# COMPUTE_CLUSTER_J7AHP0_C71SS0_0_AW4_MSMC1_CFGS0 register map
Vendor: Texas Instruments
Peripheral module from a debugger description file (folder J7_AHP).
Registers are 64-bit, read-write, reset values left out (the file's numbers can be read two ways) unless marked. A register's access mark holds for its fields unless they carry their own. Offsets are as the file gives them; lines under a group give offsets from that group; [hi:lo] are bit positions; {n}, {i} and the like mark numbered series; 'fields as' and 'values as' point back to an identical list; <NAME> marks a mode.

## COMPUTE_CLUSTER_J7AHP0_C71SS0_0_AW4_MSMC1_CFGS0
0x00 AW4_MSMC1_CFGS0_pid ro
  [31:0] REVISION — PID Revision
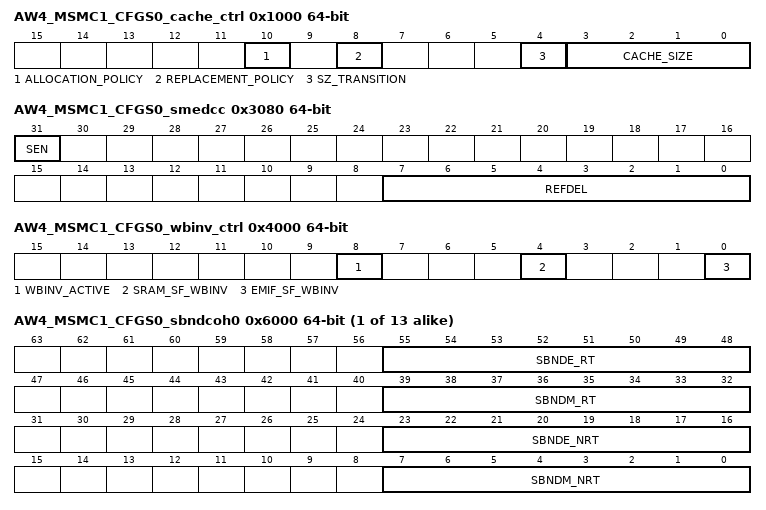
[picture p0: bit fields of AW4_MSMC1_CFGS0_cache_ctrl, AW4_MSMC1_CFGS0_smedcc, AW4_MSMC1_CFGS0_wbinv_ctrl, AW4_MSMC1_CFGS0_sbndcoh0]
0x1000 AW4_MSMC1_CFGS0_cache_ctrl access per field
  [10] ALLOCATION_POLICY rw
  [8] REPLACEMENT_POLICY rw
  [4] SZ_TRANSITION ro — Cache Size Change in Progress
  [3:0] CACHE_SIZE rw — Cache Size Control
0x1008 AW4_MSMC1_CFGS0_cache_stat access not given
0x2048 AW4_MSMC1_CFGS0_cohctrl
  [0] BCM — Broadcast Mode
0x3080 AW4_MSMC1_CFGS0_smedcc
  [31] SEN — Scrub Engine Enable
  [7:0] REFDEL — Number of Clock Cycles Between Scrubs
0x4000 AW4_MSMC1_CFGS0_wbinv_ctrl access per field
  [8] WBINV_ACTIVE ro — Writeback Invalidate in Progress
  [4] SRAM_SF_WBINV wo — SRAM Snoop Filter Writeback Invalidation Trigger
  [0] EMIF_SF_WBINV wo — EMIF Snoop Filter Writeback Invalidation Trigger
0x5000 AW4_MSMC1_CFGS0_smestat ro
  [0] NULL_SLV — Null slave error is enabled and pending
0x5008 AW4_MSMC1_CFGS0_smirstat ro
  [0] NULL_SLV — Null slave error flagged
0x5008 AW4_MSMC1_CFGS0_smirws wo
  [0] NULL_SLV — Set software null slave error
0x5010 AW4_MSMC1_CFGS0_smirc wo
  [0] NULL_SLV — Clear null slave error flag
0x5018 AW4_MSMC1_CFGS0_smiestat ro
  [0] NULL_SLV — Null slave error interrupt is enabled
0x5018 AW4_MSMC1_CFGS0_smiews wo
  [0] NULL_SLV — Enable null slave error
0x5020 AW4_MSMC1_CFGS0_smiec wo
  [0] NULL_SLV — clear null slave error interrupt enable
{0x6000+8i} AW4_MSMC1_CFGS0_sbndcoh{i} (i=0..12)
  [55:48] SBNDE_RT — Starvation Bound for Real-Time External Memory
  [39:32] SBNDM_RT — Starvation Bound for Real-Time On-Chip Memory
  [23:16] SBNDE_NRT — Starvation Bound for Non-Real-Time External Memory
  [7:0] SBNDM_NRT — Starvation Bound for Non-Real-Time On-Chip Memory
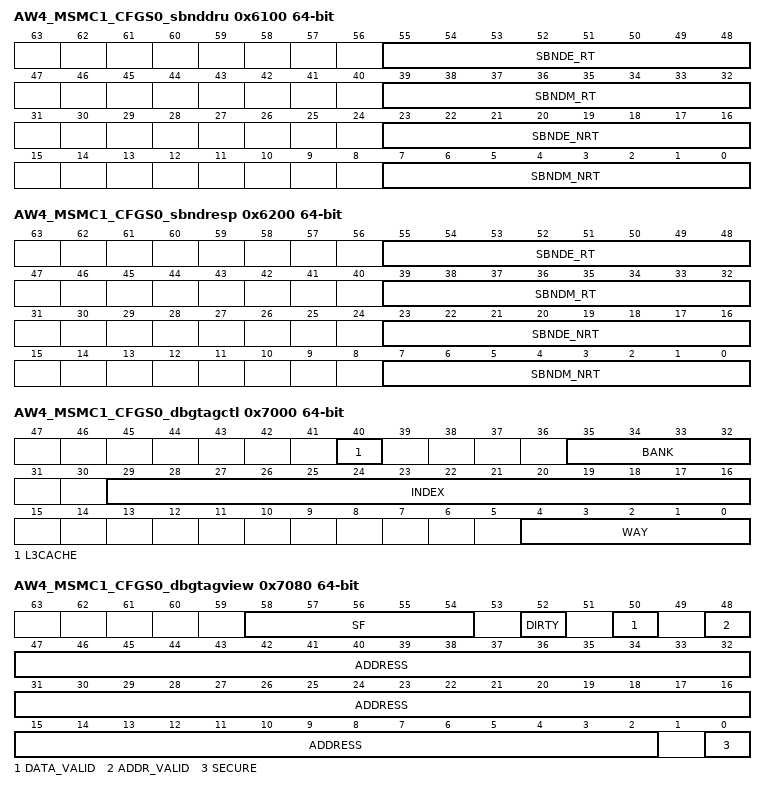
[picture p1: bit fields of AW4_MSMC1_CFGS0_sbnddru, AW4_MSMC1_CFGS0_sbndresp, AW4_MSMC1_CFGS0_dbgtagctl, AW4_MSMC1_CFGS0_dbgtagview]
0x6100 AW4_MSMC1_CFGS0_sbnddru
  fields as AW4_MSMC1_CFGS0_sbndcoh0
0x6200 AW4_MSMC1_CFGS0_sbndresp
  fields as AW4_MSMC1_CFGS0_sbndcoh0
0x7000 AW4_MSMC1_CFGS0_dbgtagctl
  [40] L3CACHE — Level 3 Cache Tag Select
  [35:32] BANK — Physical Bank Select
  [29:16] INDEX — Index Select
  [4:0] WAY — Way Select
0x7080 AW4_MSMC1_CFGS0_dbgtagview ro
  [58:54] SF — Snoop Filter
  [52] DIRTY
  [50] DATA_VALID
  [48] ADDR_VALID — Address Valid
  [47:2] ADDRESS — Tag Address
  [0] SECURE
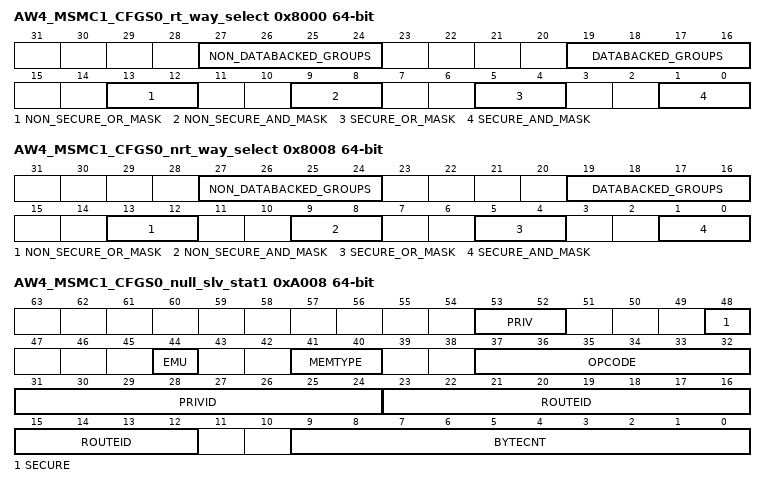
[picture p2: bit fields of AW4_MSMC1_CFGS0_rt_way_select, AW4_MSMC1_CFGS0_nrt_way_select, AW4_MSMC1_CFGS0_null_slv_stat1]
0x8000 AW4_MSMC1_CFGS0_rt_way_select
  [27:24] NON_DATABACKED_GROUPS — Number of available non-databacked way groups
  [19:16] DATABACKED_GROUPS — Number of available databacked way groups
  [13:12] NON_SECURE_OR_MASK — Non-secure transaction OR mask for way-select
  [9:8] NON_SECURE_AND_MASK — Non-secure transaction AND mask for way-select
  [5:4] SECURE_OR_MASK — Secure transaction OR mask for way-select
  [1:0] SECURE_AND_MASK — Secure transaction AND mask for way-select
0x8008 AW4_MSMC1_CFGS0_nrt_way_select
  fields as AW4_MSMC1_CFGS0_rt_way_select
0xA000 AW4_MSMC1_CFGS0_null_slv_stat0 ro
  [63:0] ADDR — Address
0xA008 AW4_MSMC1_CFGS0_null_slv_stat1 ro
  [53:52] PRIV — Privilege
  [48] SECURE
  [44] EMU — Emulation
  [41:40] MEMTYPE — Memory Type
  [37:32] OPCODE
  [31:24] PRIVID
  [23:12] ROUTEID
  [9:0] BYTECNT — Byte Count
0xA018 AW4_MSMC1_CFGS0_null_slv_cnt
  [7:0] COUNT
